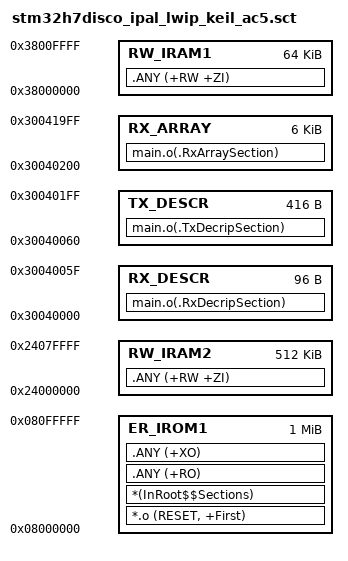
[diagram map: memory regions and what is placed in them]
; *************************************************************
; *** Scatter-Loading Description File generated by uVision ***
; *************************************************************

LR_IROM1 0x08000000 0x00100000  {    ; load region size_region
  ER_IROM1 0x08000000 0x00100000  {  ; load address = execution address
   *.o (RESET, +First)
   *(InRoot$$Sections)
   .ANY (+RO)
   .ANY (+XO)
  }
  RX_DESCR	0x30040000 0x00000060 {
  	main.o(.RxDecripSection)
  }
  TX_DESCR	0x30040060 0x000001A0 {
  	main.o(.TxDecripSection)
  }
  RX_ARRAY 	0x30040200 0x00001800 {
  	main.o(.RxArraySection)
  }
  RW_IRAM1 0x38000000 0x00010000  {  ; RW data
   .ANY (+RW +ZI)
  }
  RW_IRAM2 0x24000000 0x00080000  {
   .ANY (+RW +ZI)
  }
}

